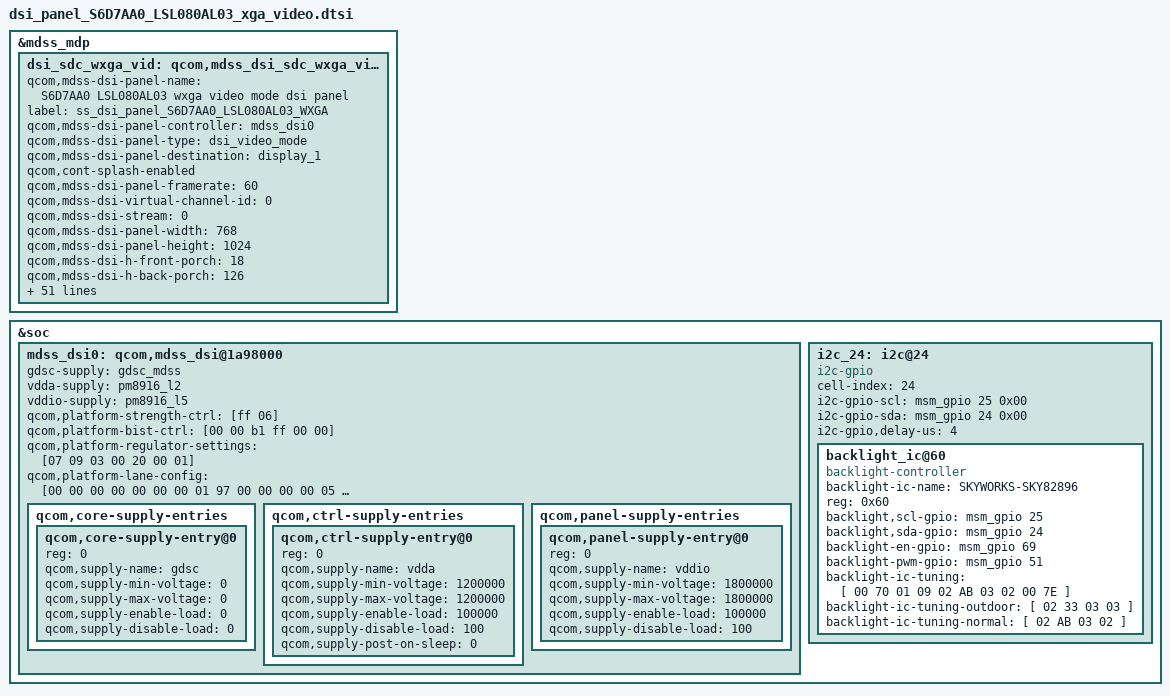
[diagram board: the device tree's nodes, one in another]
/* Copyright (c) 2013, The Linux Foundation. All rights reserved.
 *
 * This program is free software; you can redistribute it and/or modify
 * it under the terms of the GNU General Public License version 2 and
 * only version 2 as published by the Free Software Foundation.
 *
 * This program is distributed in the hope that it will be useful,
 * but WITHOUT ANY WARRANTY; without even the implied warranty of
 * MERCHANTABILITY or FITNESS FOR A PARTICULAR PURPOSE.  See the
 * GNU General Public License for more details.
 */

/*---------------------------------------------------------------------------
 * This file is autogenerated file using gcdb parser. Please do not edit it.
 * Update input XML file to add a new entry or update variable in this file
 * VERSION = "1.0"
 *---------------------------------------------------------------------------*/
&mdss_mdp {
	dsi_sdc_wxga_vid: qcom,mdss_dsi_sdc_wxga_video {
		qcom,mdss-dsi-panel-name = "S6D7AA0 LSL080AL03 wxga video mode dsi panel";
		label = "ss_dsi_panel_S6D7AA0_LSL080AL03_WXGA";
		qcom,mdss-dsi-panel-controller = <&mdss_dsi0>;
		qcom,mdss-dsi-panel-type = "dsi_video_mode";
		qcom,mdss-dsi-panel-destination = "display_1";
		qcom,cont-splash-enabled;
		qcom,mdss-dsi-panel-framerate = <60>;
		qcom,mdss-dsi-virtual-channel-id = <0>;
		qcom,mdss-dsi-stream = <0>;
		qcom,mdss-dsi-panel-width = <768>;
		qcom,mdss-dsi-panel-height = <1024>;
		qcom,mdss-dsi-h-front-porch = <18>;
		qcom,mdss-dsi-h-back-porch = <126>;
		qcom,mdss-dsi-h-pulse-width = <16>;
		qcom,mdss-dsi-h-sync-skew = <0>;
		qcom,mdss-dsi-v-back-porch = <6>;
		qcom,mdss-dsi-v-front-porch = <8>;
		qcom,mdss-dsi-v-pulse-width = <2>;
		qcom,mdss-dsi-h-left-border = <0>;
		qcom,mdss-dsi-h-right-border = <0>;
		qcom,mdss-dsi-v-top-border = <0>;
		qcom,mdss-dsi-v-bottom-border = <0>;
		qcom,mdss-dsi-bpp = <24>;
		qcom,mdss-dsi-underflow-color = <0xff>;
		qcom,mdss-dsi-border-color = <0>;
		qcom,mdss-dsi-on-command = [
               39 01 00 00 00 00 03 F0 5A 5A
               39 01 00 00 00 00 03 F1 5A 5A
               39 01 00 00 00 00 03 FC A5 A5
               39 01 00 00 00 00 03 D0 00 10
               39 01 00 00 00 00 04 C3 C7 00 29
               39 01 00 00 00 00 04 BC 01 4E A0
               39 01 00 00 00 00 06 FD 16 10 11 23 09
               39 01 00 00 00 00 07 FE 00 02 03 21 80 78
               39 01 00 00 00 00 02 B3 51
               39 01 00 00 00 00 02 53 24
               39 01 00 00 0A 00 04 F2 02 08 08
               39 01 00 00 00 00 04 C0 80 80 30
               39 01 00 00 00 00 0E CD 2E 2E 2E 2E 2E 2E 2E 2E 2E 2E 2E 2E 2E
               39 01 00 00 00 00 0E CE 00 00 00 00 00 00 00 00 00 00 00 00 00
               39 01 00 00 00 00 02 C1 03
               05 01 00 00 78 00 02 11 00
               39 00 00 00 00 00 03 F0 A5 A5
               39 01 00 00 00 00 03 F1 A5 A5
               39 01 00 00 00 00 03 FC 5A 5A
               39 01 00 00 00 00 02 35 00
               05 01 00 00 05 00 02 29 00
		];
		qcom,mdss-dsi-off-command = [
					39 01 00 00 00 00 02 22 00
					05 01 00 00 40 00 02 28 00
					05 01 00 00 0A 00 02 10 00
		];
		qcom,mdss-dsi-on-command-state = "dsi_lp_mode";
		qcom,mdss-dsi-off-command-state = "dsi_hs_mode";
		qcom,mdss-dsi-h-sync-pulse = <0>;
		qcom,mdss-dsi-bllp-eof-power-mode;
		qcom,mdss-dsi-bllp-power-mode;
		qcom,mdss-dsi-lane-0-state;
		qcom,mdss-dsi-lane-1-state;
		qcom,mdss-dsi-lane-2-state;
		qcom,mdss-dsi-lane-3-state;
		qcom,mdss-dsi-panel-timings = [6A 16 0E 00 38 3A 12 18 10 03 04 00];
		qcom,mdss-dsi-t-clk-post = <0x04>;
		qcom,mdss-dsi-t-clk-pre = <0x23>;
		qcom,mdss-dsi-bl-min-level = <1>;
		qcom,mdss-dsi-bl-max-level = <255>;
		qcom,mdss-dsi-dma-trigger = "trigger_sw";
		qcom,mdss-dsi-mdp-trigger = "none";
		qcom,mdss-dsi-bl-pmic-control-type = "bl_ctrl_dcs";
		qcom,mdss-dsi-traffic-mode = <2>;
		samsung,mdnie-tuning-enable-tft;
		qcom,esd_irq_gpio = <&msm_gpio 0 0>;
		qcom,esd-check-enabled;
		qcom,mdss-dsi-panel-status-check-mode="reg_read_irq";
		qcom,mdss-dsi-panel-status-value = <1>;
		qcom,mdss-dsi-panel-status-irq-trigger="falling";
		qcom,mdss-power-off-delay-us = <5000>;
		qcom,mdss-dsi-reset-sequence = <1 20>, <0 20>, <1 20>;
		qcom,mdss-pan-physical-width-dimension = <122>;
		qcom,mdss-pan-physical-height-dimension = <163>;
		qcom,mdss-dsi-lp11-init;
		qcom,mdss-dsi-init-delay-us = <20000>;
		qcom,mdss-dsi-force-clk-lane-hs;
	};
};
&soc {
	mdss_dsi0: qcom,mdss_dsi@1a98000 {
		gdsc-supply = <&gdsc_mdss>;
		vdda-supply = <&pm8916_l2>;
		vddio-supply = <&pm8916_l5>;
		qcom,platform-strength-ctrl = [ff 06];
		qcom,platform-bist-ctrl = [00 00 b1 ff 00 00];
		qcom,platform-regulator-settings = [07 09 03 00 20 00 01];
		qcom,platform-lane-config = [00 00 00 00 00 00 00 01 97
			00 00 00 00 05 00 00 01 97
			00 00 00 00 0a 00 00 01 97
			00 00 00 00 0f 00 00 01 97
			00 c0 00 00 00 00 00 01 bb];
		qcom,core-supply-entries {
			#address-cells = <1>;
			#size-cells = <0>;

			qcom,core-supply-entry@0 {
				reg = <0>;
				qcom,supply-name = "gdsc";
				qcom,supply-min-voltage = <0>;
				qcom,supply-max-voltage = <0>;
				qcom,supply-enable-load = <0>;
				qcom,supply-disable-load = <0>;
			};
		};
		qcom,ctrl-supply-entries {
			#address-cells = <1>;
			#size-cells = <0>;

			qcom,ctrl-supply-entry@0 {
				reg = <0>;
				qcom,supply-name = "vdda";
				qcom,supply-min-voltage = <1200000>;
				qcom,supply-max-voltage = <1200000>;
				qcom,supply-enable-load = <100000>;
				qcom,supply-disable-load = <100>;
				qcom,supply-post-on-sleep = <0>;
			};
		};
		qcom,panel-supply-entries {
			#address-cells = <1>;
			#size-cells = <0>;


			qcom,panel-supply-entry@0 {
				reg = <0>;
				qcom,supply-name = "vddio";
				qcom,supply-min-voltage = <1800000>;
				qcom,supply-max-voltage = <1800000>;
				qcom,supply-enable-load = <100000>;
				qcom,supply-disable-load = <100>;
			};
		};
	};
	i2c_24: i2c@24 {
		#address-cells = <1>;
		#size-cells = <0>;

		cell-index = <24>;
		compatible = "i2c-gpio";
		i2c-gpio-scl = <&msm_gpio 25  0x00>; /*scl gpio*/
		i2c-gpio-sda = <&msm_gpio 24 0x00>;  /*sda gpio*/
		i2c-gpio,delay-us = <4>;
		backlight_ic@60 {
			compatible = "backlight-controller";
			backlight-ic-name = "SKYWORKS-SKY82896";
			reg = <0x60>;
			backlight,scl-gpio = <&msm_gpio 25 0x00>;
			backlight,sda-gpio = <&msm_gpio 24 0x00>;
			backlight-en-gpio = <&msm_gpio 69 0x00>;
			backlight-pwm-gpio = <&msm_gpio 51 0x00>;
			backlight-ic-tuning = [
					00	70
					01	09
					02	AB
					03	02
					00	7E
			];
			backlight-ic-tuning-outdoor = [
					02	33
					03	03
			];
			backlight-ic-tuning-normal = [
					02	AB
					03	02
			];
		};
	};

};
